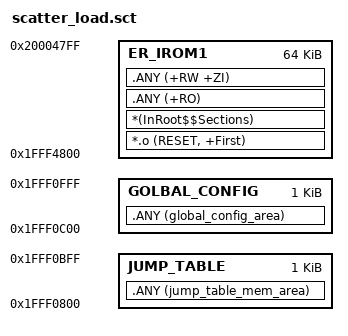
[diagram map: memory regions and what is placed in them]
; *************************************************************
; *** Scatter-Loading Description File generated by uVision ***
; *************************************************************

 ;LR_IROM1 0x1fff4000 0x00010000 {  ; load region size_region
  ;ER_IROM1 0x1fff4000 0x0008000  {  ; load address = execution address
   ;*.o (RESET, +First)
   ;*(InRoot$$Sections)
   ;*.o(.rev16_text,.revsh_text,.text)
   ;.ANY (+RO) 
   ;.ANY (+RW +ZI)
  ;}
  
  ;;RW_IRAM1 0x1fff4500 0x00003000  {  ; RW data
   ;;.ANY (+RW +ZI)
  ;;}
  ;;ER_IROM2 0x1fff4000 0x0005000  {  ; load address = execution address
   ;;.ANY (+RO) 
  ;;}  
  
  ;;RW_IRAM1 0x1fff9000 0x00001000  {  ; RW data
   ;;.ANY (+RW +ZI)
  ;;}
 
;}

LR_IROM1 0x1fff4800 0x0010000 {  ; load region size_region
  ER_IROM1 0x1fff4800 0x0010000  {  ; load address = execution address
   *.o (RESET, +First)
   *(InRoot$$Sections)  
   .ANY (+RO) 
   .ANY (+RW +ZI)
  }
}
 
LR_IROM2  0x1fff0800 0x00800 {
  JUMP_TABLE 0x1fff0800 0x00400  {
   .ANY (jump_table_mem_area) 
	
  }
  GOLBAL_CONFIG 0x1fff0c00 0x00400  {
   .ANY (global_config_area) 
	
  }  
 } 



